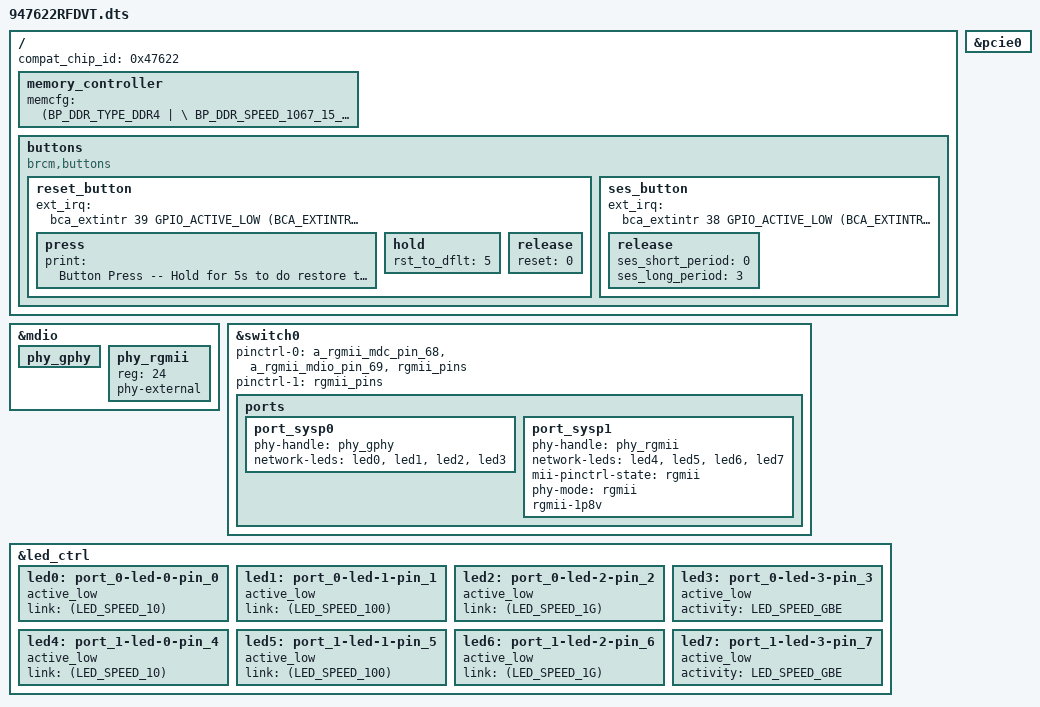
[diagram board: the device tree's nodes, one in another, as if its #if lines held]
#include "47622.dtsi"

/ {
	compat_chip_id = <0x47622>;
    memory_controller {
        memcfg = <(BP_DDR_TYPE_DDR4           | \
                   BP_DDR_SPEED_1067_15_15_15 | \
                   BP_DDR_TOTAL_SIZE_2048MB   | \
                   BP_DDR_DEVICE_WIDTH_8      | \
                   BP_DDR_TOTAL_WIDTH_16BIT   | \
                   BP_DDR_SSC_CONFIG_1)>;
    };

	buttons {
		compatible = "brcm,buttons";
		reset_button {
			ext_irq = <&bca_extintr 39 GPIO_ACTIVE_LOW (BCA_EXTINTR_TYPE_LOW_LEVEL | BCA_EXTINTR_TYPE_SENSE_EDGE)>;
			press {
				print = "Button Press -- Hold for 5s to do restore to default";
			};
			hold {
				rst_to_dflt = <5>;
			};
			release {
				reset = <0>;
			};	
		};
		ses_button {
			ext_irq = <&bca_extintr 38 GPIO_ACTIVE_LOW (BCA_EXTINTR_TYPE_LOW_LEVEL | BCA_EXTINTR_TYPE_SENSE_EDGE)>;
			release {
				ses_short_period = <0>;
				ses_long_period = <3>;
			};
		};
	};
};

&mdio {
    /* Port PHY mapping:
            port_sysp0 <-->  phy_gphy
            port_sysp1 <-->  phy_rgmii
     */
	phy_gphy {
		status = "okay";
	};

	phy_rgmii {
		reg = <24>;
		status = "okay";
		phy-external;
	};

};

&switch0 {
	pinctrl-names = "default", "rgmii"; 
	pinctrl-0 = <&a_rgmii_mdc_pin_68 &a_rgmii_mdio_pin_69 &rgmii_pins>; 
	pinctrl-1 = <&rgmii_pins>; 

	ports {
		/* fixed port configuration */
		port_sysp0 {
			phy-handle = <&phy_gphy>;
			status = "okay";
			network-leds = <&led0 &led1 &led2 &led3>;
		};
		port_sysp1 {
			phy-handle = <&phy_rgmii>;
			network-leds = <&led4 &led5 &led6 &led7>;
			mii-pinctrl-state = "rgmii";
			phy-mode = "rgmii";
			rgmii-1p8v;
			status = "okay";
		};
	};
};

&led_ctrl {
	led0: port_0-led-0-pin_0 {
		active_low;
		link = <(LED_SPEED_10)>;
		status = "okay";
	};
	led1: port_0-led-1-pin_1 {
		active_low;
		link = <(LED_SPEED_100)>;
		status = "okay";
	};
	led2: port_0-led-2-pin_2 {
		active_low;
		link = <(LED_SPEED_1G)>;
		status = "okay";
	};
	led3: port_0-led-3-pin_3 {
		active_low;
		activity = <LED_SPEED_GBE>;
		status = "okay";
	};
	led4: port_1-led-0-pin_4 {
		active_low;
		link = <(LED_SPEED_10)>;
		status = "okay";
	};
	led5: port_1-led-1-pin_5 {
		active_low;
		link = <(LED_SPEED_100)>;
		status = "okay";
	};
	led6: port_1-led-2-pin_6 {
		active_low;
		link = <(LED_SPEED_1G)>;
		status = "okay";
	};
	led7: port_1-led-3-pin_7 {
		active_low;
		activity = <LED_SPEED_GBE>;
		status = "okay";
	};
};

#if defined(CONFIG_BCM_PCIE_HCD) || defined (CONFIG_BCM_PCIE_HCD_MODULE)
&pcie0 {
	status = "okay";
};
#endif

